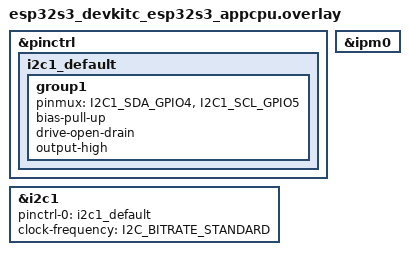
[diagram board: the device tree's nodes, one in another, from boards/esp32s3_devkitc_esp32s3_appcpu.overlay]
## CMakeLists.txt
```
cmake_minimum_required(VERSION 3.20.0)

find_package(Zephyr REQUIRED HINTS $ENV{ZEPHYR_BASE})
project(aht20_bmp280_multisensor_appcpu)

target_sources(app PRIVATE
	src/main.c
	src/ssd1306_display.c
)
```

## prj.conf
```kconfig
# 01_AHT20_BMP280_MultiSensor - core1 (appcpu) image
#
# No CONFIG_SENSOR here - this core never touches AHT20/BMP280, only
# the SSD1306 over I2C1 and the IPM mailbox from core0.

CONFIG_I2C=y
CONFIG_GPIO=y

CONFIG_IPM=y
CONFIG_ESP32_SOFT_IPM=y

CONFIG_LOG=y
CONFIG_LOG_MODE_IMMEDIATE=y

CONFIG_FPU=y
```

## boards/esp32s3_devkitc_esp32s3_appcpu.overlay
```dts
/*
 * Overlay for 01_AHT20_BMP280_MultiSensor - core1 (appcpu) image
 *
 * - I2C1 (NOT I2C0 - see core0 overlay for why) remapped to
 *   SDA=GPIO4 / SCL=GPIO5, chosen freely for this lab: not a
 *   strapping pin (0/3/45/46), not a USB-JTAG pin (19/20), and not
 *   already used by I2C0 (8/9) on the other core.
 * - No sensor devicetree nodes here on purpose - core1 never talks to
 *   AHT20 or BMP280 directly, only to the SSD1306 (probed at runtime
 *   by src/ssd1306_display.c, not declared as a devicetree node -
 *   same reasoning as the rest of this display-driver series).
 * - &ipm0 is this image's half of the core0<->core1 mailbox.
 *
 * IMPORTANT: verify the pinctrl macro names (I2C1_SDA_GPIO4 etc.) and
 * whether &i2c1 needs any additional properties beyond what's here -
 * this is this lab's first use of I2C1 in the whole curriculum, so
 * unlike I2C0 there is no prior working overlay to copy from.
 */

#include <dt-bindings/pinctrl/esp32s3-pinctrl.h>
#include <zephyr/dt-bindings/i2c/i2c.h>

&pinctrl {
	i2c1_default: i2c1_default {
		group1 {
			pinmux = <I2C1_SDA_GPIO4>, <I2C1_SCL_GPIO5>;
			bias-pull-up;
			drive-open-drain;
			output-high;
		};
	};
};

&i2c1 {
	status = "okay";
	pinctrl-0 = <&i2c1_default>;
	pinctrl-names = "default";
	clock-frequency = <I2C_BITRATE_STANDARD>; /* 100 kHz */
};

&ipm0 {
	status = "okay";
};
```

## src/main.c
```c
/*
 * main.c - 01_AHT20_BMP280_MultiSensor (core1 / appcpu image)
 *
 * This core does exactly one job: receive sensor snapshots from core0
 * over IPM and draw them on the SSD1306. It never touches I2C0, AHT20,
 * or BMP280 - see src/main.c (core0) and the design doc for why the
 * two cores each own a different physical I2C controller.
 *
 * Event flow: the ESP32 IPM driver invokes `ipm_callback()` in
 * interrupt context whenever core0 sends a message. ISR context must
 * stay short and must not do blocking I2C transfers, so the callback
 * only copies the payload into a message queue (k_msgq_put with
 * K_NO_WAIT is ISR-safe) and returns immediately. The actual OLED
 * redraw happens in `display_thread_fn()`, which blocks on
 * `k_msgq_get()` and only wakes when a new sample has actually
 * arrived - the event-driven half of this lab's design.
 *
 * core0 does NOT send on a fixed short period any more - it pushes
 * immediately when AHT20 temperature moves >=1C or BMP280 pressure
 * moves >=10 hPa since the last value it sent, plus a 1 s heartbeat so
 * this side has something to declare "alive" even during quiet
 * periods. AHT20 humidity and BMP280 temperature are "passengers" in
 * every payload - they're always included and always drawn, but they
 * never trigger a push by themselves (see core0's main.c). This side
 * only cares about elapsed time since the last arrival: if nothing
 * shows up in `sensor_msgq` for 2 s, the link is considered down.
 */

#include <zephyr/kernel.h>
#include <zephyr/device.h>
#include <zephyr/drivers/i2c.h>
#include <zephyr/drivers/ipm.h>
#include <zephyr/logging/log.h>
#include <string.h>

#include "ipm_protocol.h"
#include "ssd1306_display.h"

LOG_MODULE_REGISTER(app_appcpu, LOG_LEVEL_INF);

static const struct device *dev_i2c1 = DEVICE_DT_GET(DT_NODELABEL(i2c1));
static const struct device *dev_ipm  = DEVICE_DT_GET(DT_NODELABEL(ipm0));

/* Depth 4: core0 only ever sends one relevant message every 500 ms, so
 * this just needs enough slack to absorb a brief scheduling delay on
 * the display thread - it is not meant to buffer a long backlog.
 */
K_MSGQ_DEFINE(sensor_msgq, sizeof(struct ipm_sensor_payload), 4, 4);

/* Runs in IPM ISR context - keep it minimal. */
static void ipm_callback(const struct device *ipmdev, void *user_data,
			  uint32_t id, volatile void *data)
{
	ARG_UNUSED(ipmdev);
	ARG_UNUSED(user_data);

	if (id != IPM_SENSOR_CHANNEL) {
		return; /* not our channel - ignore */
	}

	struct ipm_sensor_payload payload;

	memcpy(&payload, (const void *)data, sizeof(payload));

	if (k_msgq_put(&sensor_msgq, &payload, K_NO_WAIT) != 0) {
		/* Queue momentarily full (display thread fell behind) -
		 * drop the oldest entry and keep the newest one, since
		 * only the latest snapshot is ever useful for a live
		 * display.
		 */
		struct ipm_sensor_payload discard;

		k_msgq_get(&sensor_msgq, &discard, K_NO_WAIT);
		k_msgq_put(&sensor_msgq, &payload, K_NO_WAIT);
	}
}

static void format_fixed1(float value, char *buf, size_t buf_len)
{
	bool negative = value < 0.0f;
	float abs_value = negative ? -value : value;
	int scaled = (int)(abs_value * 10.0f + 0.5f);

	snprintf(buf, buf_len, "%s%d.%d", negative ? "-" : "", scaled / 10, scaled % 10);
}

static void render_payload(const struct ipm_sensor_payload *p, bool stale)
{
	char line[22];
	char num[8];

	ssd1306_clear();

	/* Link health goes first/top - it qualifies how much to trust
	 * everything else on the screen.
	 */
	ssd1306_draw_text(0, 0, stale ? "LINK: FAIL" : "LINK: OK");

	if (p->aht20_valid) {
		format_fixed1(p->aht20_temp_c, num, sizeof(num));
		snprintf(line, sizeof(line), "AHT20 T:%sC", num);
		ssd1306_draw_text(2, 0, line);

		format_fixed1(p->aht20_humidity_pct, num, sizeof(num));
		snprintf(line, sizeof(line), "AHT20 H:%s%%", num);
		ssd1306_draw_text(3, 0, line);
	} else {
		ssd1306_draw_text(2, 0, "AHT20 ---");
	}

	if (p->bmp280_valid) {
		format_fixed1(p->bmp280_temp_c, num, sizeof(num));
		snprintf(line, sizeof(line), "BMP280 T:%sC", num);
		ssd1306_draw_text(5, 0, line);

		snprintf(line, sizeof(line), "BMP280 P:%d hPa",
			 (int)(p->bmp280_pressure_hpa + 0.5f));
		ssd1306_draw_text(6, 0, line);
	} else {
		ssd1306_draw_text(5, 0, "BMP280 ---");
	}

	ssd1306_flush();
}

static void display_thread_fn(void *p1, void *p2, void *p3)
{
	ARG_UNUSED(p1);
	ARG_UNUSED(p2);
	ARG_UNUSED(p3);

	int ret = ssd1306_display_init(dev_i2c1);

	if (ret) {
		LOG_ERR("SSD1306 init failed: %d - display thread exiting", ret);
		return;
	}

	ssd1306_draw_text(2, 0, "WAITING FOR");
	ssd1306_draw_text(3, 0, "CORE0...");
	ssd1306_flush();

	bool have_data = false;
	struct ipm_sensor_payload last_payload = { 0 };

	while (1) {
		struct ipm_sensor_payload payload;
		/* core0's heartbeat alone guarantees a message at least
		 * every 1 s even with no threshold crossings, so 2000 ms
		 * of total silence means something upstream stalled
		 * (sensor threads stuck, IPM channel jammed, core0
		 * crashed, etc) rather than just "values held steady".
		 */
		int ret2 = k_msgq_get(&sensor_msgq, &payload, K_MSEC(2000));

		if (ret2 == 0) {
			last_payload = payload;
			have_data = true;
			render_payload(&last_payload, false);
		} else if (have_data) {
			render_payload(&last_payload, true);
		}
		/* else: never received anything yet - keep showing the
		 * "WAITING FOR CORE0..." screen drawn above.
		 */
	}
}

K_THREAD_DEFINE(display_tid, 2048, display_thread_fn, NULL, NULL, NULL, 6, 0, 0);

int main(void)
{
	LOG_INF("01_AHT20_BMP280_MultiSensor (core1/appcpu) starting");

	if (!device_is_ready(dev_i2c1)) {
		LOG_ERR("I2C1 bus not ready");
		return -1;
	}
	if (!device_is_ready(dev_ipm)) {
		LOG_ERR("IPM device not ready - cannot receive sensor data from core0");
		return -1;
	}

	ipm_register_callback(dev_ipm, ipm_callback, NULL);
	ipm_set_enabled(dev_ipm, 1);

	/* display_thread_fn is already running (K_THREAD_DEFINE, 0 delay). */
	return 0;
}
```

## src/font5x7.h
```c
/*
 * font5x7.h
 *
 * Minimal original 5x7 dot-matrix font for the SSD1306 text
 * renderer used across this multi-sensor lab series. Only the
 * characters this series actually prints (labels, digits,
 * units, punctuation) are defined; anything else falls back
 * to a blank glyph in font5x7_lookup().
 *
 * Layout: 5 columns per glyph, column-major, bit0 = top row,
 * 7 rows tall (fits an 8px-tall character cell with 1px gap).
 */

#ifndef FONT5X7_H_
#define FONT5X7_H_

#include <stdint.h>
#include <stddef.h>
#include <zephyr/sys/util.h> /* ARRAY_SIZE */

#define FONT5X7_WIDTH  5
#define FONT5X7_HEIGHT 7

static const uint8_t FONT_SPACE[FONT5X7_WIDTH] = {0x00, 0x00, 0x00, 0x00, 0x00};
static const uint8_t FONT_BANG[FONT5X7_WIDTH] = {0x00, 0x5F, 0x5F, 0x00, 0x00};
static const uint8_t FONT_PERCENT[FONT5X7_WIDTH] = {0x21, 0x10, 0x0C, 0x02, 0x21};
static const uint8_t FONT_DASH[FONT5X7_WIDTH] = {0x08, 0x08, 0x08, 0x08, 0x08};
static const uint8_t FONT_DOT[FONT5X7_WIDTH] = {0x00, 0x60, 0x60, 0x00, 0x00};
static const uint8_t FONT_0[FONT5X7_WIDTH] = {0x3E, 0x51, 0x49, 0x45, 0x3E};
static const uint8_t FONT_1[FONT5X7_WIDTH] = {0x00, 0x42, 0x7F, 0x40, 0x00};
static const uint8_t FONT_2[FONT5X7_WIDTH] = {0x42, 0x61, 0x51, 0x49, 0x46};
static const uint8_t FONT_3[FONT5X7_WIDTH] = {0x22, 0x41, 0x49, 0x49, 0x36};
static const uint8_t FONT_4[FONT5X7_WIDTH] = {0x18, 0x14, 0x12, 0x7F, 0x10};
static const uint8_t FONT_5[FONT5X7_WIDTH] = {0x27, 0x45, 0x45, 0x45, 0x39};
static const uint8_t FONT_6[FONT5X7_WIDTH] = {0x3C, 0x4A, 0x49, 0x49, 0x30};
static const uint8_t FONT_7[FONT5X7_WIDTH] = {0x01, 0x71, 0x09, 0x05, 0x03};
static const uint8_t FONT_8[FONT5X7_WIDTH] = {0x36, 0x49, 0x49, 0x49, 0x36};
static const uint8_t FONT_9[FONT5X7_WIDTH] = {0x06, 0x49, 0x49, 0x29, 0x1E};
static const uint8_t FONT_COLON[FONT5X7_WIDTH] = {0x00, 0x36, 0x36, 0x00, 0x00};
static const uint8_t FONT_A[FONT5X7_WIDTH] = {0x7C, 0x12, 0x11, 0x12, 0x7C};
static const uint8_t FONT_B[FONT5X7_WIDTH] = {0x7F, 0x49, 0x49, 0x49, 0x36};
static const uint8_t FONT_C[FONT5X7_WIDTH] = {0x3E, 0x41, 0x41, 0x41, 0x41};
static const uint8_t FONT_D[FONT5X7_WIDTH] = {0x7F, 0x41, 0x41, 0x41, 0x3E};
static const uint8_t FONT_E[FONT5X7_WIDTH] = {0x7F, 0x49, 0x49, 0x49, 0x41};
static const uint8_t FONT_F[FONT5X7_WIDTH] = {0x7F, 0x09, 0x09, 0x09, 0x01};
static const uint8_t FONT_G[FONT5X7_WIDTH] = {0x3E, 0x41, 0x49, 0x49, 0x79};
static const uint8_t FONT_H[FONT5X7_WIDTH] = {0x7F, 0x08, 0x08, 0x08, 0x7F};
static const uint8_t FONT_I[FONT5X7_WIDTH] = {0x41, 0x41, 0x7F, 0x41, 0x41};
static const uint8_t FONT_L[FONT5X7_WIDTH] = {0x7F, 0x40, 0x40, 0x40, 0x40};
static const uint8_t FONT_M[FONT5X7_WIDTH] = {0x7F, 0x02, 0x04, 0x02, 0x7F};
static const uint8_t FONT_N[FONT5X7_WIDTH] = {0x7F, 0x02, 0x04, 0x08, 0x7F};
static const uint8_t FONT_O[FONT5X7_WIDTH] = {0x3E, 0x41, 0x41, 0x41, 0x3E};
static const uint8_t FONT_P[FONT5X7_WIDTH] = {0x7F, 0x09, 0x09, 0x09, 0x06};
static const uint8_t FONT_R[FONT5X7_WIDTH] = {0x7F, 0x09, 0x19, 0x29, 0x46};
static const uint8_t FONT_S[FONT5X7_WIDTH] = {0x46, 0x49, 0x49, 0x49, 0x31};
static const uint8_t FONT_T[FONT5X7_WIDTH] = {0x01, 0x01, 0x7F, 0x01, 0x01};
static const uint8_t FONT_U[FONT5X7_WIDTH] = {0x3F, 0x40, 0x40, 0x40, 0x3F};
static const uint8_t FONT_V[FONT5X7_WIDTH] = {0x1F, 0x20, 0x40, 0x20, 0x1F};
static const uint8_t FONT_W[FONT5X7_WIDTH] = {0x7F, 0x20, 0x18, 0x20, 0x7F};
static const uint8_t FONT_Y[FONT5X7_WIDTH] = {0x03, 0x04, 0x78, 0x04, 0x03};
static const uint8_t FONT_K[FONT5X7_WIDTH] = {0x7F, 0x08, 0x14, 0x22, 0x41};
static const uint8_t FONT_h[FONT5X7_WIDTH] = {0x7F, 0x08, 0x04, 0x04, 0x78};
static const uint8_t FONT_a[FONT5X7_WIDTH] = {0x20, 0x54, 0x54, 0x54, 0x78};

struct font5x7_entry {
	char ch;
	const uint8_t *cols;
};

static const struct font5x7_entry font5x7_table[] = {
	{ ' ', FONT_SPACE },
	{ '!', FONT_BANG },
	{ '%', FONT_PERCENT },
	{ '-', FONT_DASH },
	{ '.', FONT_DOT },
	{ '0', FONT_0 },
	{ '1', FONT_1 },
	{ '2', FONT_2 },
	{ '3', FONT_3 },
	{ '4', FONT_4 },
	{ '5', FONT_5 },
	{ '6', FONT_6 },
	{ '7', FONT_7 },
	{ '8', FONT_8 },
	{ '9', FONT_9 },
	{ ':', FONT_COLON },
	{ 'A', FONT_A },
	{ 'B', FONT_B },
	{ 'C', FONT_C },
	{ 'D', FONT_D },
	{ 'E', FONT_E },
	{ 'F', FONT_F },
	{ 'G', FONT_G },
	{ 'H', FONT_H },
	{ 'I', FONT_I },
	{ 'L', FONT_L },
	{ 'M', FONT_M },
	{ 'N', FONT_N },
	{ 'O', FONT_O },
	{ 'P', FONT_P },
	{ 'R', FONT_R },
	{ 'S', FONT_S },
	{ 'T', FONT_T },
	{ 'U', FONT_U },
	{ 'V', FONT_V },
	{ 'W', FONT_W },
	{ 'Y', FONT_Y },
	{ 'K', FONT_K },
	{ 'h', FONT_h },
	{ 'a', FONT_a },
};

/* Returns the 5-byte column array for `ch`, or NULL if the
 * character isn't in the table (caller should render a blank).
 */
static inline const uint8_t *font5x7_lookup(char ch)
{
	for (size_t i = 0; i < ARRAY_SIZE(font5x7_table); i++) {
		if (font5x7_table[i].ch == ch) {
			return font5x7_table[i].cols;
		}
	}
	return NULL;
}

#endif /* FONT5X7_H_ */
```

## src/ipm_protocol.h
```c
/*
 * ipm_protocol.h
 *
 * Shared between the procpu (core0, src/) and appcpu (core1, remote/src/)
 * images. Sysbuild compiles these as two completely independent Zephyr
 * applications, so there is no shared build target to enforce a single
 * copy of this file - keep both copies byte-for-byte identical.
 */

#ifndef IPM_PROTOCOL_H_
#define IPM_PROTOCOL_H_

#include <stdint.h>

/* IPM channel used for procpu -> appcpu sensor forwarding. Per this
 * project's IPM convention (see roadmap Lab 18 notes), channels 0/1
 * are reserved by the platform and 2/3 are free for application use.
 * This lab claims channel 2; channel 3 is left free for a future lab.
 */
#define IPM_SENSOR_CHANNEL 2

/* All four measured values are displayed on core1, but only two of
 * them (aht20_temp_c, bmp280_pressure_hpa) ever trigger an immediate
 * push on their own - see main.c. Humidity and BMP280 temperature are
 * "passengers": they ride along in the same payload whenever the
 * other value in their sensor triggers a send, or whenever the
 * heartbeat fires, but never trigger a send by themselves.
 *
 * Must stay within the ESP32 IPM driver's 64-byte per-message payload
 * limit (trivially true here).
 */
struct ipm_sensor_payload {
	float aht20_temp_c;
	float aht20_humidity_pct;
	uint8_t aht20_valid;

	float bmp280_temp_c;
	float bmp280_pressure_hpa;
	uint8_t bmp280_valid;
};

#endif /* IPM_PROTOCOL_H_ */
```

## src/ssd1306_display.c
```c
/*
 * ssd1306_display.c
 *
 * See ssd1306_display.h for the rationale behind driving this panel
 * with raw I2C calls instead of the in-tree display subsystem.
 */

#include "ssd1306_display.h"
#include "font5x7.h"

#include <zephyr/drivers/i2c.h>
#include <zephyr/logging/log.h>
#include <string.h>
#include <errno.h>

LOG_MODULE_REGISTER(ssd1306, LOG_LEVEL_INF);

/* Candidate 7-bit addresses; 0x3C is by far the most common on 4-pin
 * I2C SSD1306 breakout boards, 0x3D shows up on a few variants.
 */
static const uint8_t candidate_addrs[] = { 0x3C, 0x3D };

static const struct device *dev_i2c;
static uint8_t panel_addr;

/* GDDRAM mirror. Contiguous in memory (page-major), so it can be
 * pushed to the panel with a single memcpy + single I2C write.
 */
static uint8_t framebuffer[SSD1306_PAGES][SSD1306_WIDTH];

/* Standard SSD1306 128x64 init sequence (see SSD1306 datasheet,
 * section "Command Table"). Sent as ONE command stream: the control
 * byte 0x00 with the Co bit cleared tells the panel every following
 * byte is a command, so this entire array can go out as a single
 * i2c_write() alongside that one control byte.
 */
static const uint8_t init_cmds[] = {
	0xAE,       /* display off */
	0xD5, 0x80, /* clock divide ratio / oscillator frequency */
	0xA8, 0x3F, /* multiplex ratio = 64 - 1 */
	0xD3, 0x00, /* display offset = 0 */
	0x40,       /* display start line = 0 */
	0x8D, 0x14, /* charge pump enable (required for most 3.3V-only modules) */
	0x20, 0x00, /* memory addressing mode = horizontal */
	0xA1,       /* segment remap (column 127 -> SEG0) */
	0xC8,       /* COM output scan direction, remapped */
	0xDA, 0x12, /* COM pins hardware configuration */
	0x81, 0xCF, /* contrast control */
	0xD9, 0xF1, /* pre-charge period */
	0xDB, 0x40, /* VCOMH deselect level */
	0xA4,       /* resume RAM content display (not "all pixels on") */
	0xA6,       /* normal display (not inverted) */
	/* Fix the addressing window to the full panel once. In horizontal
	 * addressing mode the GDDRAM pointer auto-wraps from the last
	 * column of one page to the first column of the next, and wraps
	 * from page 7 back to page 0 after a full 1024-byte write - so
	 * this only needs to be set once, not before every flush.
	 */
	0x21, 0x00, 0x7F, /* column address range: 0..127 */
	0x22, 0x00, 0x07, /* page address range: 0..7 */
	0xAF,             /* display on */
};

static int send_cmd_stream(uint8_t addr, const uint8_t *cmds, size_t len)
{
	/* control byte (0x00 = command stream) + payload, single buffer */
	uint8_t buf[64];

	if (len + 1 > sizeof(buf)) {
		return -ENOMEM;
	}

	buf[0] = 0x00;
	memcpy(&buf[1], cmds, len);

	return i2c_write(dev_i2c, buf, len + 1, addr);
}

static int probe_panel(void)
{
	for (size_t i = 0; i < ARRAY_SIZE(candidate_addrs); i++) {
		/* A real command (display-off) doubles as the probe: a
		 * NACK from an unpopulated address returns a non-zero
		 * errno here rather than corrupting anything, since only
		 * the addressed device (if any) reacts to it.
		 */
		int ret = send_cmd_stream(candidate_addrs[i], init_cmds, 1);

		if (ret == 0) {
			panel_addr = candidate_addrs[i];
			LOG_INF("SSD1306 found at 0x%02X", panel_addr);
			return 0;
		}
	}

	LOG_ERR("SSD1306 not found at 0x3C or 0x3D");
	return -ENODEV;
}

int ssd1306_display_init(const struct device *i2c_dev)
{
	int ret;

	dev_i2c = i2c_dev;

	ret = probe_panel();
	if (ret) {
		return ret;
	}

	/* Boot stabilization delay, same convention as the OLED I2C labs
	 * earlier in this series.
	 */
	k_msleep(100);

	ret = send_cmd_stream(panel_addr, init_cmds, sizeof(init_cmds));
	if (ret) {
		LOG_ERR("SSD1306 init command stream failed: %d", ret);
		return ret;
	}

	ssd1306_clear();
	return ssd1306_flush();
}

void ssd1306_clear(void)
{
	memset(framebuffer, 0, sizeof(framebuffer));
}

void ssd1306_draw_text(uint8_t page, uint8_t col, const char *text)
{
	if (page >= SSD1306_PAGES) {
		return;
	}

	for (const char *p = text; *p != '\0'; p++) {
		if (col + FONT5X7_WIDTH > SSD1306_WIDTH) {
			break; /* clip, don't wrap */
		}

		const uint8_t *glyph = font5x7_lookup(*p);

		if (glyph != NULL) {
			memcpy(&framebuffer[page][col], glyph, FONT5X7_WIDTH);
		} else {
			memset(&framebuffer[page][col], 0, FONT5X7_WIDTH);
		}

		col += FONT5X7_WIDTH;

		/* 1px inter-character gap */
		if (col < SSD1306_WIDTH) {
			framebuffer[page][col] = 0x00;
			col += 1;
		}
	}
}

int ssd1306_flush(void)
{
	/* control byte (0x40 = data stream) + full 1024-byte framebuffer,
	 * single contiguous buffer, single i2c_write() - see the header
	 * comment for why this must never be split into two messages.
	 */
	static uint8_t tx_buf[1 + sizeof(framebuffer)];

	tx_buf[0] = 0x40;
	memcpy(&tx_buf[1], framebuffer, sizeof(framebuffer));

	return i2c_write(dev_i2c, tx_buf, sizeof(tx_buf), panel_addr);
}
```
